# fpga register map
File version: 1.0
memory-mapped fpga registers over qspi/ospi
Registers are 32-bit, read-write, reset 0x0 unless marked. A register's access mark holds for its fields unless they carry their own. Offsets are from the block's base; lines under a group give offsets from that group; [hi:lo] are bit positions; {n}, {i} and the like mark numbered series; 'fields as' and 'values as' point back to an identical list; <NAME> marks a mode.

## Memory map
0x90000000 system0 size 0x40 — system block 0
0x90000200 led size 0x40 — led control block
0x90000300 buzzer size 0x40 — buzzer control block
0x90000400 io size 0x40 — io control block
0x90000800 ws2812_0 size 0x40 — ws2812 RGB LED block
0x90000900 ws2812_1 size 0x40 — ws2812 RGB LED block (second instance)
0x90000A00 loadcell0 size 0x40 — hx717 dual channel 24-bit load cell adc. all three registers share one 16-byte OctoSPI prefetch line, so reading any one of them causes reads of all of them; no register here has a read side effect
0x90000C00 encoders size 0x40 — encoders control block
0x90000D00 steppers size 0x80 — 8-channel stepper motor step/dir pulse generator (2 banks of 4)
0x90000E00 timer_pwm size 0x100 — 4 independent 8-bit timers (source clock, 8-bit prescaler, 8-bit auto-reload) feeding 12 flexibly-mapped PWM output channels (PM1-4, OT1-8)
0x9000FF00 system1 size 0x40 — system block 1

## system0 — system block 0
Base 0x90000000
0x00 ident ro reset 0xFACEB00B — device identifier
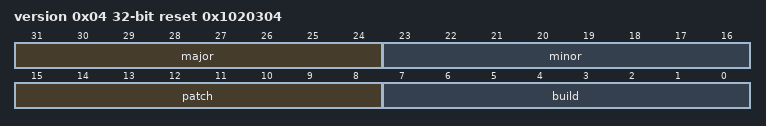
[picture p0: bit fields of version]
0x04 version ro reset 0x1020304 — version information
  [31:24] major, [23:16] minor, [15:8] patch, [7:0] build

## led — led control block
Base 0x90000200
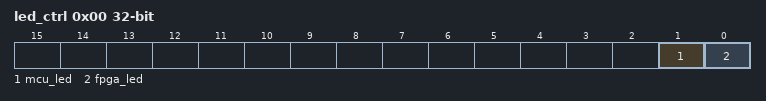
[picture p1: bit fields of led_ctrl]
0x00 led_ctrl — led control register
  [1] mcu_led — mcu activity led (0 = off)
  [0] fpga_led — fpga activity led (0 = off)

## buzzer — buzzer control block
Base 0x90000300
0x00 buzzer_ctrl — buzzer control register
  [0] buzzer — buzzer control (0 = off)

## io — io control block
Base 0x90000400
0x00 io_ctrl ro — io control register
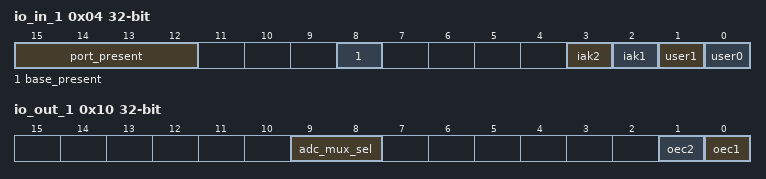
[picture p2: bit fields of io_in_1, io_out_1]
0x04 io_in_1 ro
  [15:12] port_present — port present detect
  [8] base_present — base present detect
  [3] iak2 — optical input 2 (optical isolator anode cathode)
  [2] iak1 — optical input 1 (optical isolator anode cathode)
  [1] user1 — user 1 button (1 = pressed)
  [0] user0 — user 0 button (1 = pressed)
0x08 io_in_2 ro
  [7:0] din — digital in 8 to 1 (ordering = 7:0)
0x10 io_out_1
  [9:8] adc_mux_sel — ADC Mux input select
  [1] oec2 — optical output 2 (optical isolator emitter collector)
  [0] oec1 — optical output 1 (optical isolator emitter collector)

## ws2812_0 — ws2812 RGB LED block
Base 0x90000800
Same registers: ws2812_1 0x90000900
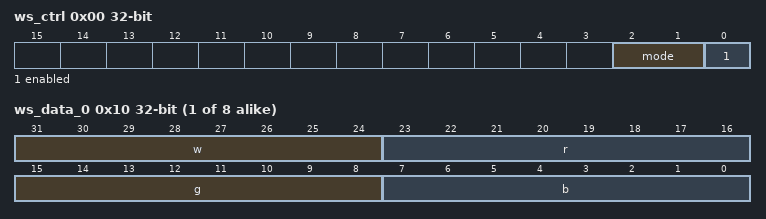
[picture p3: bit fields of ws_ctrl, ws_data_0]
0x00 ws_ctrl — led control register
  [2:1] mode — ws2812 color mode
    0=RGB (rgb ordering); 1=RGBW (rgbw ordering); 2=GRB (grb ordering); 3=GRBW (grbw ordering)
  [0] enabled — enable led output (1 = on)
0x04 ws_tx_config — ws2812 transmit configuration
  [7:0] leds_count
{0x10+4i} ws_data_{i} (i=0..7) — rgb(w) input
  [31:24] w, [23:16] r, [15:8] g, [7:0] b

## encoders — encoders control block
Base 0x90000C00
0x00 enc_ctrl — encoders control register
  [0] reset — reset encoders (1 = reset)
0x04 enc_set_count_a wo — set encoder a counter
  [15:0] value — encoder counter value
0x08 enc_set_count_b wo — set encoder b counter
  [15:0] value — encoder counter value
0x0C enc_set_count_c wo — set encoder c counter
  [15:0] value — encoder counter value
0x10 enc_set_count_x wo — set encoder x counter
  [15:0] value — encoder counter value
0x14 enc_set_count_y wo — set encoder y counter
  [15:0] value — encoder counter value
0x18 enc_set_count_z wo — set encoder z counter
  [15:0] value — encoder counter value
0x20 enc_count_a ro — encoder a counter
  [15:0] value — encoder counter value
0x24 enc_count_b ro — encoder b counter
  [15:0] value — encoder counter value
0x28 enc_count_c ro — encoder c counter
  [15:0] value — encoder counter value
0x2C enc_count_x ro — encoder x counter
  [15:0] value — encoder counter value
0x30 enc_count_y ro — encoder y counter
  [15:0] value — encoder counter value
0x34 enc_count_z ro — encoder z counter
  [15:0] value — encoder counter value
